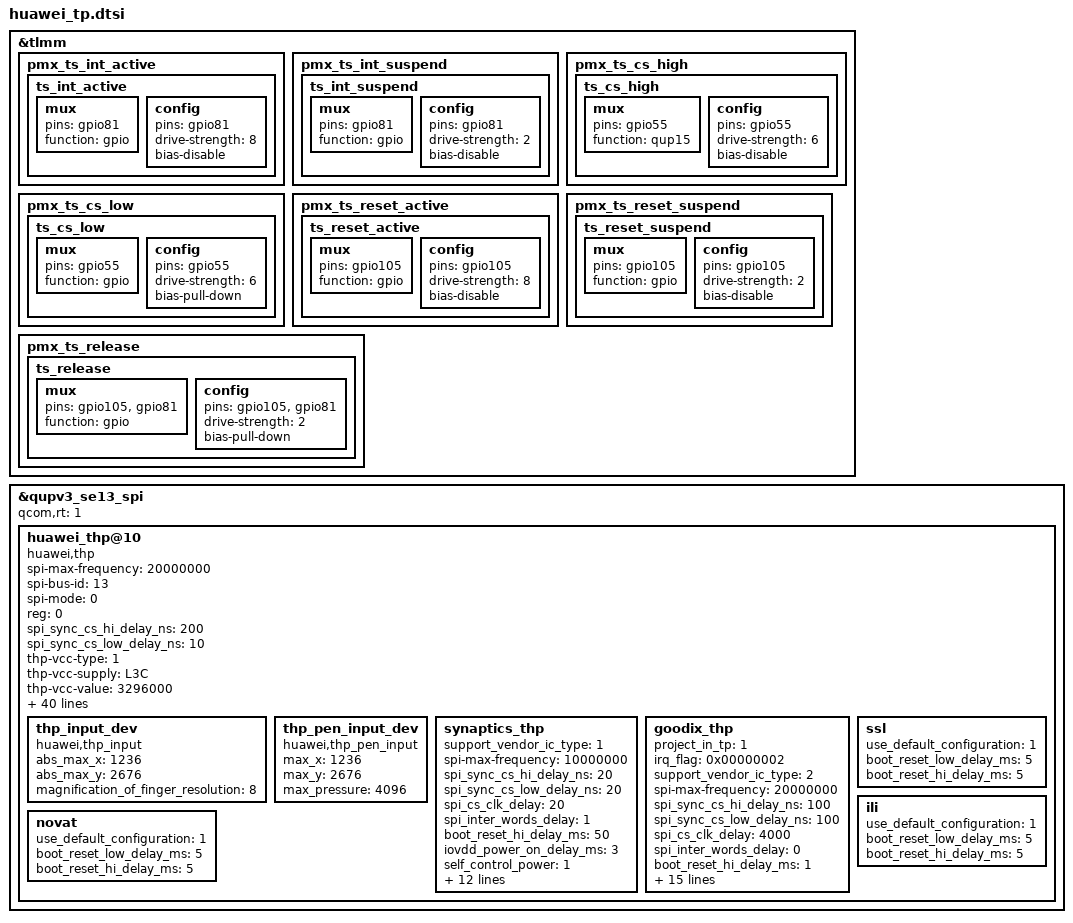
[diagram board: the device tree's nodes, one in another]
/* touch panel config */
&tlmm {
	pmx_ts_int_active {
		ts_int_active: ts_int_active {
			mux {
				pins = "gpio81";
				function = "gpio";
			};

			config {
				pins = "gpio81";
				drive-strength = <8>;
				bias-disable;
			};
		};
	};

	pmx_ts_int_suspend {
		ts_int_suspend: ts_int_suspend {
			mux {
				pins = "gpio81";
				function = "gpio";
			};

			config {
				pins = "gpio81";
				drive-strength = <2>;
				bias-disable;
			};
		};
	};

	pmx_ts_cs_high {
		ts_cs_high: ts_cs_high {
			mux {
				pins = "gpio55";
				function = "qup15";
			};

			config {
				pins = "gpio55";
				drive-strength = <6>;
				bias-disable;
			};
		};
	};

	pmx_ts_cs_low {
		ts_cs_low: ts_cs_low {
			mux {
				pins = "gpio55";
				function = "gpio";
			};

			config {
				pins = "gpio55";
				drive-strength = <6>;
				bias-pull-down;
			};
		};
	};

	pmx_ts_reset_active {
		ts_reset_active: ts_reset_active {
			mux {
				pins = "gpio105";
				function = "gpio";
			};

			config {
				pins = "gpio105";
				drive-strength = <8>;
				bias-disable;
			};
		};
	};

	pmx_ts_reset_suspend {
		ts_reset_suspend: ts_reset_suspend {
			mux {
				pins = "gpio105";
				function = "gpio";
			};

			config {
				pins = "gpio105";
				drive-strength = <2>;
				bias-disable;
			};
		};
	};

	pmx_ts_release {
		ts_release: ts_release {
			mux {
				pins = "gpio105", "gpio81";
				function = "gpio";
			};

			config {
				pins = "gpio105", "gpio81";
				drive-strength = <2>;
				bias-pull-down;
			};
		};
	};
};

&qupv3_se13_spi{
	status = "ok";
	#address-cells = <1>;
	#size-cells = <0>;
	qcom,rt = <1>;
	huawei_thp@10 {
		compatible = "huawei,thp";
		status = "ok";
		/* SPI Config */
		spi-max-frequency = <20000000>;
		spi-bus-id = <13>;
		spi-mode = <0>;
		reg = <0>;
		spi_sync_cs_hi_delay_ns = <200>;
		spi_sync_cs_low_delay_ns = <10>;

		/* Power Config */
		thp-vcc-type = <1>;
		thp-vcc-supply = <&L3C>;
		thp-vcc-value = <3296000>;
		thp-iovdd-type = <1>;
		thp-iovdd-supply = <&L2C>;
		thp-iovdd-value = <1800000>;

		/* Timing */
		boot_reset_hi_delay_ms = <1>;
		boot_reset_low_delay_ms = <0>;
		boot_reset_after_delay_ms = <0>;
		resume_reset_after_delay_ms = <1>;
		suspend_reset_after_delay_ms = <1>;
		use_mdelay = <1>;

		/* GPIO Config */
		irq_flag = <0x00000002>;
		interrupt-parent = <&tlmm>;
		interrupts = <81 0>;
		rst_gpio = <&tlmm 105 0x00>;
		irq_gpio = <&tlmm 81 0x00>;
		cs_gpio = <&tlmm 55 0x00>;
		pinctrl-names = "default", "idle", "state_cs_output1", "state_cs_output0";
		pinctrl-0 = <&ts_int_active &ts_reset_active>;
		pinctrl-1 = <&ts_int_suspend &ts_reset_suspend>;
		pinctrl-2 = <&ts_cs_high>;
		pinctrl-3 = <&ts_cs_low>;
		support_no_cs_for_qcom = <1>;
		support_control_cs_off = <1>;

		/* Feature Config */
		support_pinctrl = <1>;
		pinctrl_init_enable = <1>;
		pt_station_test = <0>;
		support_gesture_mode = <1>;
		hide_product_info_en = <1>;
		supported_func_indicater = <0x00>;
		fast_booting_solution = <1>;
		support_fingerprint_switch = <1>;
		pen_supported = <0>;
		pen_mt_enable_flag = <0>;
		project_in_tp = <1>;
		aod_display_support = <1>;
		support_factory_mode_extra_cmd = <2>;
		need_notify_to_roi_algo = <1>;
		use_ap_gesture = <1>;
		use_thp_queue = <1>;
		supported_charger = <1>;
		need_enable_irq_wake = <1>;
		aptouch_daemon_version = <3>;

		thp_input_dev {
			compatible = "huawei,thp_input";
			abs_max_x = <1236>;
			abs_max_y = <2676>;
			magnification_of_finger_resolution = <8>;
		};
		thp_pen_input_dev {
			compatible = "huawei,thp_pen_input";
			max_x = <1236>;
			max_y = <2676>;
			max_pressure = <4096>;
		};
		synaptics_thp {
			support_vendor_ic_type = <1>;
			spi-max-frequency = <10000000>;
			spi_sync_cs_hi_delay_ns = <20>;
			spi_sync_cs_low_delay_ns = <20>;
			spi_cs_clk_delay = <20>; // add (spi_cs_clk_delay * 2 / spi_clk) delay
			spi_inter_words_delay = <1>;
			boot_reset_hi_delay_ms = <50>;
			iovdd_power_on_delay_ms = <3>;
			self_control_power = <1>;
			need_huge_memory_in_spi = <1>;
			/* IRQF_TRIGGER_LOW 0x00000008 */
			irq_flag = <0x00000008>;
			avoid_low_level_irq_storm = <1>;
			not_control_irq_in_irq_handler = <1>;
			support_get_frame_read_once = <1>;
			support_fingerprint_switch = <1>;
			aod_display_support = <1>;
			use_aod_power_ctrl_notify = <1>;
			suspend_delayms_early_to_before = <150>;
			suspend_delayms_before_to_later = <15>;
			resume_delayms_early_to_later = <50>;
			need_enable_irq_wake = <1>;
		};
		goodix_thp {
			status = "ok";
			project_in_tp = <1>;
			irq_flag = <0x00000002>;
			support_vendor_ic_type = <2>;
			spi-max-frequency = <20000000>;
			spi_sync_cs_hi_delay_ns = <100>;
			spi_sync_cs_low_delay_ns = <100>;
			spi_cs_clk_delay = <4000>; // add (spi_cs_clk_delay * 2 / spi_clk) delay
			spi_inter_words_delay = <0>;
			boot_reset_hi_delay_ms = <1>;
			boot_reset_low_delay_ms = <1>;
			boot_reset_after_delay_ms = <100>;
			resume_reset_after_delay_ms = <2>;
			support_gesture_mode = <1>;
			use_ap_gesture = <1>;
			need_resume_reset = <1>;
			support_fingerprint_switch = <1>;
			aod_display_support = <1>;
			gesture_mode_double_tap = <1>;
			use_aod_power_ctrl_notify = <1>;
			suspend_delayms_early_to_before = <150>;
			suspend_delayms_before_to_later = <15>;
			resume_delayms_early_to_later = <50>;
			need_enable_irq_wake = <1>;
			irq_sync_method = <1>;
		};
		ssl {
			use_default_configuration = <1>;
			boot_reset_low_delay_ms = <5>;
			boot_reset_hi_delay_ms = <5>;
		};
		ili {
			use_default_configuration = <1>;
			boot_reset_low_delay_ms = <5>;
			boot_reset_hi_delay_ms = <5>;
		};
		novat {
			use_default_configuration = <1>;
			boot_reset_low_delay_ms = <5>;
			boot_reset_hi_delay_ms = <5>;
		};
	};
};
